# afe_dac_reva register map
Registers are 32-bit, access not given, no defined reset value unless marked. A register's access mark holds for its fields unless they carry their own. Offsets are from the block's base; lines under a group give offsets from that group; [hi:lo] are bit positions; {n}, {i} and the like mark numbered series; 'fields as' and 'values as' point back to an identical list; <NAME> marks a mode.

## Memory map
0x4FC00000 AFE_DAC size 0x200 — Analog Front End DAC on Stacked Die via SPI

## AFE_DAC — Analog Front End DAC on Stacked Die via SPI
Base 0x4FC00000
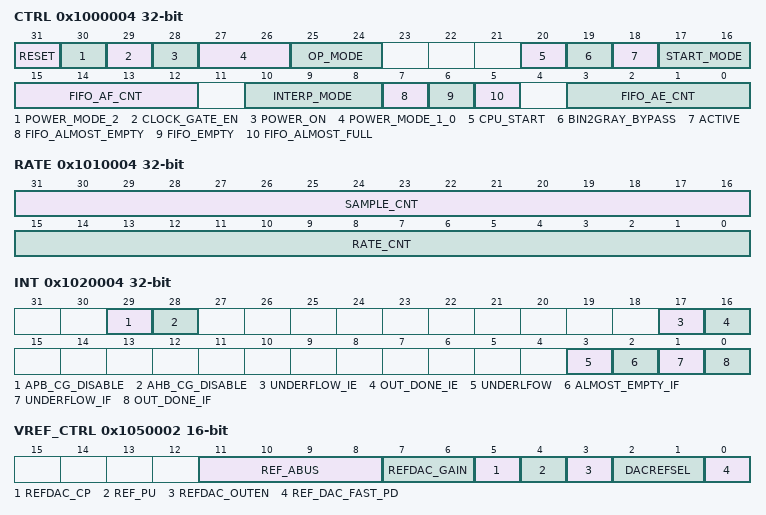
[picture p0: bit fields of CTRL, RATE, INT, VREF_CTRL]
0x1000004 CTRL — Control Register
  [31] RESET — Description not included
  [30] POWER_MODE_2 — Description not included
    0=POWLVL0_1 (Description not included); 1=POWLVL2_3 (Description not included)
  [29] CLOCK_GATE_EN — Description not included
  [28] POWER_ON — Description not included
  [27:26] POWER_MODE_1_0 — Description not included
    1=POWLVL0 (Description not included); 3=POWLVL1 (Description not included); 1=POWLVL2 (Description not included); 3=POWLVL3 (Description not included)
  [25:24] OP_MODE — Description not included
    0=OUTPUT_WHEN_FIFO_AVAIL (Description not included); 1=OUTPUT_ONCE_AT_RATE_CNT (Description not included); 2=RESERVED (Description not included); 3=OUTPUT_SAMPLE_CNT_AT_RATE_CNT (Description not included)
  [20] CPU_START — Description not included
  [19] BIN2GRAY_BYPASS — Description not included
  [18] ACTIVE — Description not included
  [17:16] START_MODE — Description not included
    0=START_WHEN_FIFO_NOT_EMPTY (Description not included); 1=START_ON_ADC_START_STROBE (Description not included); 2=START_WHEN_CPU_START_WRITTEN (Description not included); 3=RESERVED (Description not included)
  [15:12] FIFO_AF_CNT — Description not included
  [10:8] INTERP_MODE — Description not included
    0=DISABLED (Description not included); 1=2_TO_1_INTERPOLATION (Description not included); 2=4_TO_1_INTERPOLATION (Description not included); 3=8_TO_1_INTERPOLATION (Description not included)
  [7] FIFO_ALMOST_EMPTY — Description not included
  [6] FIFO_EMPTY — Description not included
  [5] FIFO_ALMOST_FULL — Description not included
  [3:0] FIFO_AE_CNT — Description not included
0x1010004 RATE — Rate/Sample Control
  [31:16] SAMPLE_CNT — Description not included
  [15:0] RATE_CNT — Description not included
0x1020004 INT — Interrupt Flags and Enable/Disable
  [29] APB_CG_DISABLE — Description not included
  [28] AHB_CG_DISABLE — Description not included
  [17] UNDERFLOW_IE — Description not included
  [16] OUT_DONE_IE — Description not included
  [3] UNDERLFOW — Description not included
  [2] ALMOST_EMPTY_IF — Description not included
  [1] UNDERFLOW_IF — Description not included
  [0] OUT_DONE_IF — Description not included
0x1030004 REG — Description not included
0x1040004 TRIM — DAC TRIM
0x1050002 VREF_CTRL 16-bit — DAC VREF Control
  [11:8] REF_ABUS — Description not included
  [7:6] REFDAC_GAIN — Description not included
    0=DEFAULT_GAIN (Description not included); 1=HIGHEST_GAIN (Description not included)
  [5] REFDAC_CP — Description not included
  [4] REF_PU — Description not included
  [3] REFDAC_OUTEN — Description not included
  [2:1] DACREFSEL — Description not included
    0=VOLTS_1_024 (Description not included); 1=VOLTS_1_500 (Description not included); 2=VOLTS_2_048 (Description not included); 3=VOLTS_2_500 (Description not included)
  [0] REF_DAC_FAST_PD — Description not included
0x1060002 FIFO 16-bit — DAC FIFO
  [15:0] FIFO_DATA — Description not included
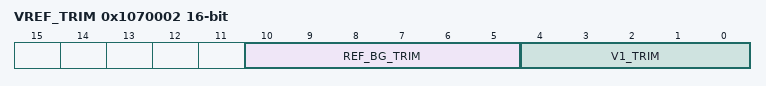
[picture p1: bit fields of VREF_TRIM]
0x1070002 VREF_TRIM 16-bit — Control behavior of GPIO1
  [10:5] REF_BG_TRIM — Description not included
  [4:0] V1_TRIM — Description not included
